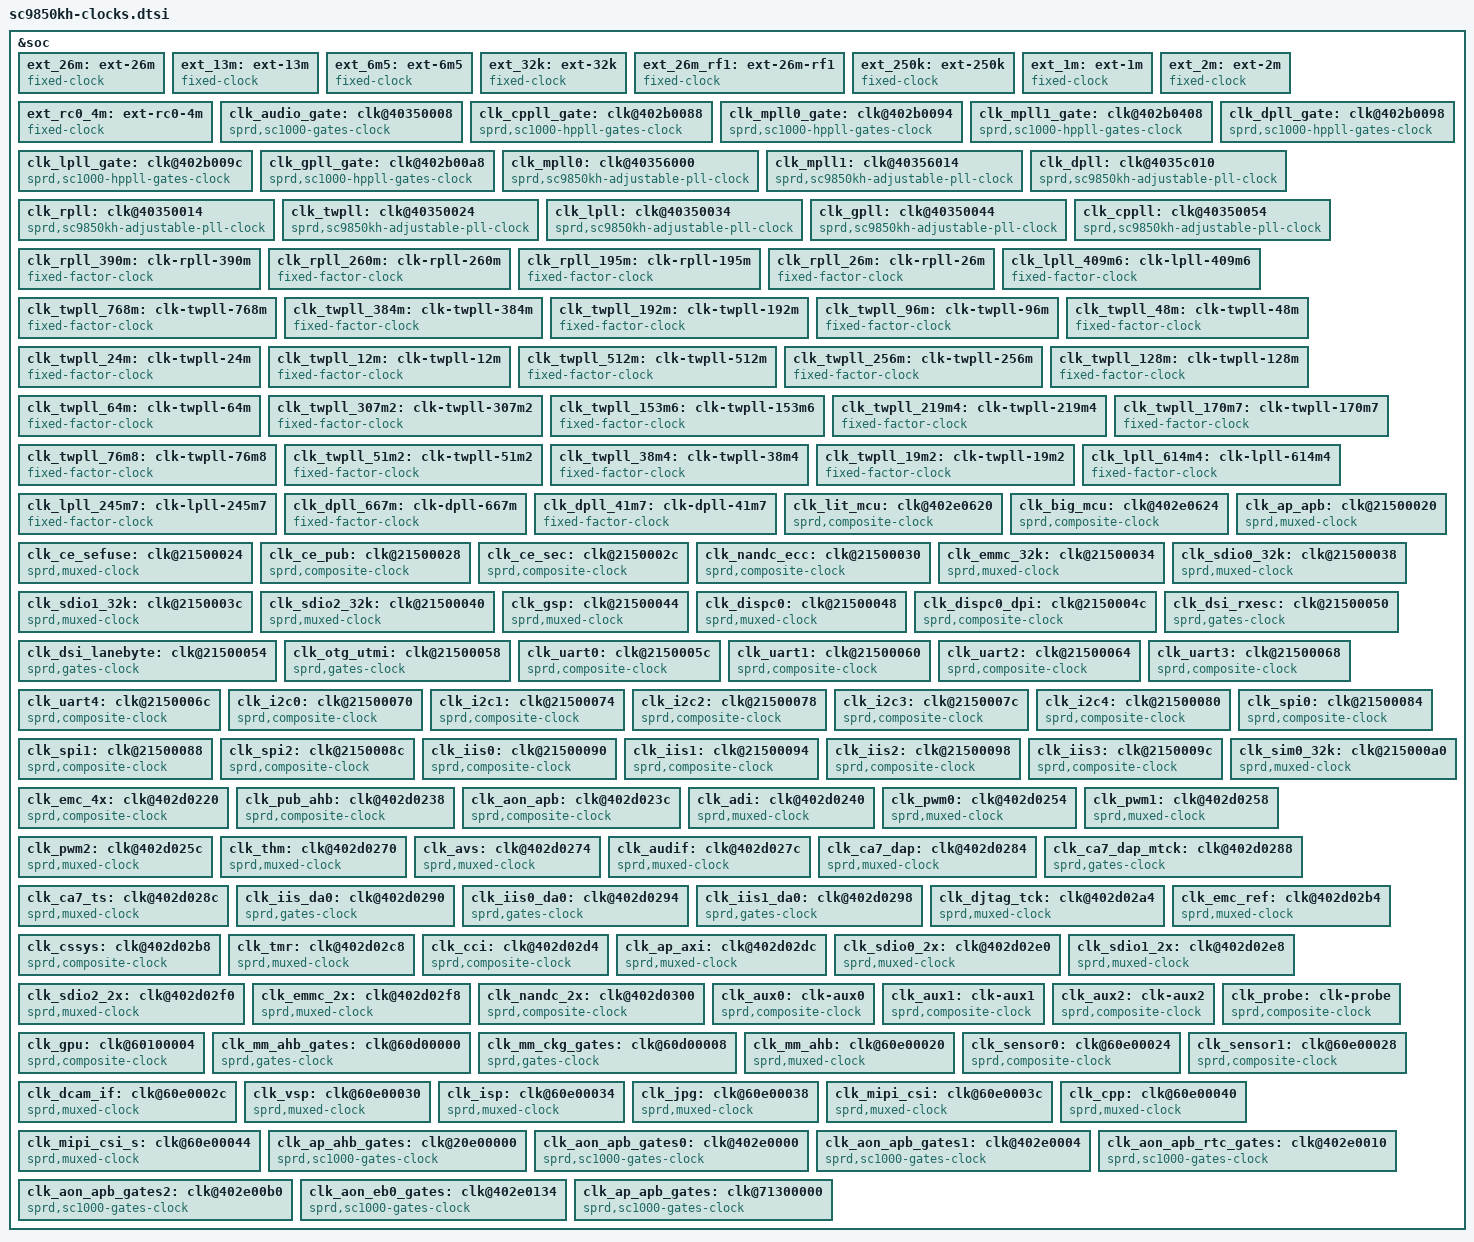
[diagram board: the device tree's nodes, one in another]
/*
 * Spreadtrum SC985x SoC DTS file
 *
 * Copyright (C) 2015, Spreadtrum Communications Inc.
 *
 * This file is licensed under a dual GPLv2 or X11 license.
 */

&soc {
	ext_26m: ext-26m {
		compatible = "fixed-clock";
		#clock-cells = <0>;
		clock-frequency = <26000000>;
		clock-output-names = "ext_26m";
	};

	ext_13m: ext-13m {
		compatible = "fixed-clock";
		#clock-cells = <0>;
		clock-frequency = <13000000>;
		clock-output-names = "ext_13m";
	};

	ext_6m5: ext-6m5 {
		compatible = "fixed-clock";
		#clock-cells = <0>;
		clock-frequency = <6500000>;
		clock-output-names = "ext_6m5";
	};

	ext_32k: ext-32k {
		compatible = "fixed-clock";
		#clock-cells = <0>;
		clock-frequency = <32768>;
		clock-output-names = "ext_32k";
	};

	ext_26m_rf1: ext-26m-rf1 {
		compatible = "fixed-clock";
		#clock-cells = <0>;
		clock-frequency = <26000000>;
		clock-output-names = "ext_26m_rf1";
	};

	ext_250k: ext-250k {
		compatible = "fixed-clock";
		#clock-cells = <0>;
		clock-frequency = <250000>;
		clock-output-names = "ext_250k";
	};

	ext_1m: ext-1m {
		compatible = "fixed-clock";
		#clock-cells = <0>;
		clock-frequency = <1000000>;
		clock-output-names = "ext_1m";
	};

	ext_2m: ext-2m {
		compatible = "fixed-clock";
		#clock-cells = <0>;
		clock-frequency = <2000000>;
		clock-output-names = "ext_2m";
	};

	ext_rc0_4m: ext-rc0-4m {
		compatible = "fixed-clock";
		#clock-cells = <0>;
		clock-frequency = <4000000>;
		clock-output-names = "ext_rc0_4m";
	};

	clk_audio_gate: clk@40350008 {
		compatible = "sprd,sc1000-gates-clock";
		#clock-cells = <1>;
		sprd,gates-msk = <0x80000>;
		reg = <0x0 0x40350008 0x0 0x3000>;
		clocks = <&ext_26m>;
		clock-output-names = "clk_audio_gate";
	};

	/* PLL gates */
	clk_cppll_gate: clk@402b0088 {
		compatible = "sprd,sc1000-hppll-gates-clock";
		#clock-cells = <1>;
		sprd,gates-msk = <0x1>;
		reg = <0 0x402b0088 0 0x3000>;
		clocks = <&ext_26m>;
		clock-output-names = "clk_cppll_gate";
	};

	clk_mpll0_gate: clk@402b0094 {
		compatible = "sprd,sc1000-hppll-gates-clock";
		#clock-cells = <1>;
		sprd,gates-msk = <0x1>;
		reg = <0 0x402b0094 0 0x3000>;
		clocks = <&ext_26m>;
		clock-output-names = "clk_mpll0_gate";
	};

	clk_mpll1_gate: clk@402b0408 {
		compatible = "sprd,sc1000-hppll-gates-clock";
		#clock-cells = <1>;
		sprd,gates-msk = <0x1>;
		reg = <0 0x402b0408 0 0x3000>;
		clocks = <&ext_26m>;
		clock-output-names = "clk_mpll1_gate";
	};

	clk_dpll_gate: clk@402b0098 {
		compatible = "sprd,sc1000-hppll-gates-clock";
		#clock-cells = <1>;
		sprd,gates-msk = <0x1>;
		reg = <0 0x402b0098 0 0x3000>;
		clocks = <&ext_26m>;
		clock-output-names = "clk_dpll_gate";
	};

	clk_lpll_gate: clk@402b009c {
		compatible = "sprd,sc1000-hppll-gates-clock";
		#clock-cells = <1>;
		sprd,gates-msk = <0x1>;
		reg = <0 0x402b009c 0 0x3000>;
		clocks = <&ext_26m>;
		clock-output-names = "clk_lpll_gate";
	};

	clk_gpll_gate: clk@402b00a8 {
		compatible = "sprd,sc1000-hppll-gates-clock";
		#clock-cells = <1>;
		sprd,gates-msk = <0x1>;
		reg = <0 0x402b00a8 0 0x3000>;
		clocks = <&ext_26m>;
		clock-output-names = "clk_gpll_gate";
	};

	/* PLL Clocks */
	clk_mpll0: clk@40356000 {
		compatible = "sprd,sc9850kh-adjustable-pll-clock";
		#clock-cells = <0>;
		reg = <0 0x40356000 0 0x4>,
		      <0 0x40356004 0 0x4>,
		      <0 0x40356008 0 0x4>;
		clocks = <&clk_mpll0_gate 0>;
		clock-output-names = "clk_mpll0";
	};

	clk_mpll1: clk@40356014 {
		compatible = "sprd,sc9850kh-adjustable-pll-clock";
		#clock-cells = <0>;
		reg = <0 0x40356014 0 0x4>,
		      <0 0x40356018 0 0x4>,
		      <0 0x4035601c 0 0x4>;
		clocks = <&clk_mpll1_gate 0>;
		clock-output-names = "clk_mpll1";
	};

	clk_dpll: clk@4035c010 {
		compatible = "sprd,sc9850kh-adjustable-pll-clock";
		#clock-cells = <0>;
		reg = <0 0x4035c010 0 0x4>,
		      <0 0x4035c014 0 0x4>;
		clocks = <&clk_dpll_gate 0>;
		clock-output-names = "clk_dpll";
	};

	clk_rpll: clk@40350014 {
		compatible = "sprd,sc9850kh-adjustable-pll-clock";
		#clock-cells = <0>;
		reg = <0 0x40350014 0 0x4>,
		      <0 0x40350018 0 0x4>,
		      <0 0x4035001c 0 0x4>;
		clocks = <&ext_26m>;
		clock-output-names = "clk_rpll";
	};

	clk_twpll: clk@40350024 {
		compatible = "sprd,sc9850kh-adjustable-pll-clock";
		#clock-cells = <0>;
		reg = <0 0x40350024 0 0x4>,
		      <0 0x40350028 0 0x4>,
		      <0 0x4035002c 0 0x4>;
		clocks = <&ext_26m>;
		clock-output-names = "clk_twpll";
	};

	clk_lpll: clk@40350034 {
		compatible = "sprd,sc9850kh-adjustable-pll-clock";
		#clock-cells = <0>;
		reg = <0 0x40350034 0 0x4>,
		      <0 0x40350038 0 0x4>,
		      <0 0x4035003c 0 0x4>;
		clocks = <&clk_lpll_gate 0>;
		clock-output-names = "clk_lpll";
	};

	clk_gpll: clk@40350044 {
		compatible = "sprd,sc9850kh-adjustable-pll-clock";
		#clock-cells = <0>;
		reg = <0 0x40350044 0 0x4>,
		      <0 0x40350048 0 0x4>,
		      <0 0x4035004c 0 0x4>;
		clocks = <&clk_gpll_gate 0>;
		clock-output-names = "clk_gpll";
	};


	clk_cppll: clk@40350054 {
		compatible = "sprd,sc9850kh-adjustable-pll-clock";
		#clock-cells = <0>;
		reg = <0 0x40350054 0 0x4>,
		      <0 0x40350058 0 0x4>,
		      <0 0x4035005c 0 0x4>;
		clocks = <&clk_cppll_gate 0>;
		clock-output-names = "clk_cppll";
	};

	/* RPLL divider clocks */
	clk_rpll_390m: clk-rpll-390m {
		compatible = "fixed-factor-clock";
		#clock-cells = <0>;
		clock-mult = <1>;
		clock-div  = <2>;
		clocks = <&clk_rpll>;
		clock-output-names = "clk_rpll_390m";
	};

	clk_rpll_260m: clk-rpll-260m {
		compatible = "fixed-factor-clock";
		#clock-cells = <0>;
		clock-mult = <1>;
		clock-div  = <3>;
		clocks = <&clk_rpll>;
		clock-output-names = "clk_rpll_260m";
	};

	clk_rpll_195m: clk-rpll-195m {
		compatible = "fixed-factor-clock";
		#clock-cells = <0>;
		clock-mult = <1>;
		clock-div  = <4>;
		clocks = <&clk_rpll>;
		clock-output-names = "clk_rpll_195m";
	};

	clk_rpll_26m: clk-rpll-26m {
		compatible = "fixed-factor-clock";
		#clock-cells = <0>;
		clock-mult = <1>;
		clock-div  = <30>;
		clocks = <&clk_rpll>;
		clock-output-names = "clk_rpll_26m";
	};

	/* LPLL divider clocks */
	clk_lpll_409m6: clk-lpll-409m6 {
		compatible = "fixed-factor-clock";
		#clock-cells = <0>;
		clock-mult = <1>;
		clock-div  = <3>;
		clocks = <&clk_lpll>;
		clock-output-names = "clk_lpll_409m6";
	};

	/* TWPLL divider clocks */
	clk_twpll_768m: clk-twpll-768m {
		compatible = "fixed-factor-clock";
		#clock-cells = <0>;
		clock-mult = <1>;
		clock-div  = <2>;
		clocks = <&clk_twpll>;
		clock-output-names = "clk_twpll_768m";
	};

	clk_twpll_384m: clk-twpll-384m {
		compatible = "fixed-factor-clock";
		#clock-cells = <0>;
		clock-mult = <1>;
		clock-div  = <4>;
		clocks = <&clk_twpll>;
		clock-output-names = "clk_twpll_384m";
	};

	clk_twpll_192m: clk-twpll-192m {
		compatible = "fixed-factor-clock";
		#clock-cells = <0>;
		clock-mult = <1>;
		clock-div  = <8>;
		clocks = <&clk_twpll>;
		clock-output-names = "clk_twpll_192m";
	};

	clk_twpll_96m: clk-twpll-96m {
		compatible = "fixed-factor-clock";
		#clock-cells = <0>;
		clock-mult = <1>;
		clock-div  = <16>;
		clocks = <&clk_twpll>;
		clock-output-names = "clk_twpll_96m";
	};

	clk_twpll_48m: clk-twpll-48m {
		compatible = "fixed-factor-clock";
		#clock-cells = <0>;
		clock-mult = <1>;
		clock-div  = <32>;
		clocks = <&clk_twpll>;
		clock-output-names = "clk_twpll_48m";
	};

	clk_twpll_24m: clk-twpll-24m {
		compatible = "fixed-factor-clock";
		#clock-cells = <0>;
		clock-mult = <1>;
		clock-div  = <64>;
		clocks = <&clk_twpll>;
		clock-output-names = "clk_twpll_24m";
	};

	clk_twpll_12m: clk-twpll-12m {
		compatible = "fixed-factor-clock";
		#clock-cells = <0>;
		clock-mult = <1>;
		clock-div  = <128>;
		clocks = <&clk_twpll>;
		clock-output-names = "clk_twpll_12m";
	};

	clk_twpll_512m: clk-twpll-512m {
		compatible = "fixed-factor-clock";
		#clock-cells = <0>;
		clock-mult = <1>;
		clock-div  = <3>;
		clocks = <&clk_twpll>;
		clock-output-names = "clk_twpll_512m";
	};

	clk_twpll_256m: clk-twpll-256m {
		compatible = "fixed-factor-clock";
		#clock-cells = <0>;
		clock-mult = <1>;
		clock-div  = <6>;
		clocks = <&clk_twpll>;
		clock-output-names = "clk_twpll_256m";
	};

	clk_twpll_128m: clk-twpll-128m {
		compatible = "fixed-factor-clock";
		#clock-cells = <0>;
		clock-mult = <1>;
		clock-div  = <12>;
		clocks = <&clk_twpll>;
		clock-output-names = "clk_twpll_128m";
	};

	clk_twpll_64m: clk-twpll-64m {
		compatible = "fixed-factor-clock";
		#clock-cells = <0>;
		clock-mult = <1>;
		clock-div  = <24>;
		clocks = <&clk_twpll>;
		clock-output-names = "clk_twpll_64m";
	};

	clk_twpll_307m2: clk-twpll-307m2 {
		compatible = "fixed-factor-clock";
		#clock-cells = <0>;
		clock-mult = <1>;
		clock-div  = <5>;
		clocks = <&clk_twpll>;
		clock-output-names = "clk_twpll_307m2";
	};

	clk_twpll_153m6: clk-twpll-153m6 {
		compatible = "fixed-factor-clock";
		#clock-cells = <0>;
		clock-mult = <1>;
		clock-div  = <10>;
		clocks = <&clk_twpll>;
		clock-output-names = "clk_twpll_153m6";
	};

	clk_twpll_219m4: clk-twpll-219m4 {
		compatible = "fixed-factor-clock";
		#clock-cells = <0>;
		clock-mult = <1>;
		clock-div  = <7>;
		clocks = <&clk_twpll>;
		clock-output-names = "clk_twpll_219m4";
	};

	clk_twpll_170m7: clk-twpll-170m7 {
		compatible = "fixed-factor-clock";
		#clock-cells = <0>;
		clock-mult = <1>;
		clock-div  = <9>;
		clocks = <&clk_twpll>;
		clock-output-names = "clk_twpll_170m7";
	};

	clk_twpll_76m8: clk-twpll-76m8 {
		compatible = "fixed-factor-clock";
		#clock-cells = <0>;
		clock-mult = <1>;
		clock-div  = <20>;
		clocks = <&clk_twpll>;
		clock-output-names = "clk_twpll_76m8";
	};

	clk_twpll_51m2: clk-twpll-51m2 {
		compatible = "fixed-factor-clock";
		#clock-cells = <0>;
		clock-mult = <1>;
		clock-div  = <30>;
		clocks = <&clk_twpll>;
		clock-output-names = "clk_twpll_51m2";
	};

	clk_twpll_38m4: clk-twpll-38m4 {
		compatible = "fixed-factor-clock";
		#clock-cells = <0>;
		clock-mult = <1>;
		clock-div  = <40>;
		clocks = <&clk_twpll>;
		clock-output-names = "clk_twpll_38m4";
	};

	clk_twpll_19m2: clk-twpll-19m2 {
		compatible = "fixed-factor-clock";
		#clock-cells = <0>;
		clock-mult = <1>;
		clock-div  = <80>;
		clocks = <&clk_twpll>;
		clock-output-names = "clk_twpll_19m2";
	};

	/* LTEPLL0 divider clock */
	clk_lpll_614m4: clk-lpll-614m4 {
		compatible = "fixed-factor-clock";
		#clock-cells = <0>;
		clock-mult = <1>;
		clock-div = <2>;
		clocks = <&clk_lpll>;
		clock-output-names = "clk_lpll_614m4";
	};

	clk_lpll_245m7: clk-lpll-245m7 {
		compatible = "fixed-factor-clock";
		#clock-cells = <0>;
		clock-mult = <1>;
		clock-div = <5>;
		clocks = <&clk_lpll>;
		clock-output-names = "clk_lpll_245m7";
	};
	/* DPLL divider clock */
	clk_dpll_667m: clk-dpll-667m {
		compatible = "fixed-factor-clock";
		#clock-cells = <0>;
		clock-mult = <1>;
		clock-div = <2>;
		clocks = <&clk_dpll>;
		clock-output-names = "clk_dpll_667m";
	};

	clk_dpll_41m7: clk-dpll-41m7 {
		compatible = "fixed-factor-clock";
		#clock-cells = <0>;
		clock-mult = <1>;
		clock-div = <32>;
		clocks = <&clk_dpll>;
		clock-output-names = "clk_dpll_41m7";
	};

	clk_lit_mcu: clk@402e0620 {
		compatible = "sprd,composite-clock";
		#clock-cells = <0>;
		reg = <0 0x402e0620 0 0x4>;	/* select reg and divider reg */
		sprd,mux-msk = <0xf>;
		sprd,div-msk = <0x70>;
		clocks = <&ext_26m>, <&clk_twpll_76m8>, <&clk_twpll_256m>,
			<&clk_twpll_384m>, <&clk_twpll_512m>, <&clk_twpll_768m>,
			<&clk_lpll>, <&clk_lpll>, <&clk_mpll0>;
		clock-output-names = "clk_lit_mcu";
	};

	clk_big_mcu: clk@402e0624 {
		compatible = "sprd,composite-clock";
		#clock-cells = <0>;
		reg = <0 0x402e0624 0 0x4>;	/* select reg and divider reg */
		sprd,mux-msk = <0xf>;
		sprd,div-msk = <0x70>;
		clocks = <&ext_26m>, <&clk_twpll_76m8>, <&clk_twpll_256m>,
			<&clk_twpll_384m>, <&clk_twpll_512m>, <&clk_twpll_768m>,
			<&clk_lpll>, <&clk_lpll>, <&clk_mpll1>;
		clock-output-names = "clk_big_mcu";
	};

	/* Ap clocks */
	clk_ap_apb: clk@21500020 {
		compatible = "sprd,muxed-clock";
		#clock-cells = <0>;
		reg = <0 0x21500020 0 0x4>;
		sprd,mux-msk = <0x3>;
		clocks = <&ext_26m>, <&clk_twpll_64m>, <&clk_twpll_96m>,
			 <&clk_twpll_128m>;
		clock-output-names = "clk_ap_apb";
	};

	clk_ce_sefuse: clk@21500024 {
		compatible = "sprd,muxed-clock";
		#clock-cells = <0>;
		reg = <0 0x21500024 0 0x4>;
		sprd,mux-msk = <0x1>;
		clocks = <&ext_26m>;
		clock-output-names = "clk_ce_sefuse";
	};

	clk_ce_pub: clk@21500028 {
		compatible = "sprd,composite-clock";
		#clock-cells = <0>;
		reg = <0 0x21500028 0 0x4>;
		sprd,mux-msk = <0x1>;
		sprd,div-msk = <0x700>;
		clocks = <&ext_26m>, <&clk_twpll_256m>;
		clock-output-names = "clk_ce_pub";
	};

	clk_ce_sec: clk@2150002c {
		compatible = "sprd,composite-clock";
		#clock-cells = <0>;
		reg = <0 0x2150002c 0 0x4>;
		sprd,mux-msk = <0x1>;
		sprd,div-msk = <0x700>;
		clocks = <&ext_26m>, <&clk_twpll_256m>;
		clock-output-names = "clk_ce_sec";
	};

	clk_nandc_ecc: clk@21500030 {
		compatible = "sprd,composite-clock";
		#clock-cells = <0>;
		reg = <0 0x21500030 0 0x4>;
		sprd,mux-msk = <0x1>;
		sprd,div-msk = <0x700>;
		clocks = <&ext_26m>, <&clk_twpll_256m>, <&clk_twpll_307m2>;
		clock-output-names = "clk_nandc_ecc";
	};

	clk_emmc_32k: clk@21500034 {
		compatible = "sprd,muxed-clock";
		#clock-cells = <0>;
		reg = <0 0x21500034 0 0x4>;
		sprd,mux-msk = <0x1>;
		clocks = <&ext_32k>, <&ext_26m>;
		clock-output-names = "clk_emmc_32k";
	};

	clk_sdio0_32k: clk@21500038 {
		compatible = "sprd,muxed-clock";
		#clock-cells = <0>;
		reg = <0 0x21500038 0 0x4>;
		sprd,mux-msk = <0x1>;
		clocks = <&ext_32k>, <&ext_26m>;
		clock-output-names = "clk_sdio0_32k";
	};

	clk_sdio1_32k: clk@2150003c {
		compatible = "sprd,muxed-clock";
		#clock-cells = <0>;
		reg = <0 0x2150003c 0 0x4>;
		sprd,mux-msk = <0x1>;
		clocks = <&ext_32k>, <&ext_26m>;
		clock-output-names = "clk_sdio1_32k";
	};

	clk_sdio2_32k: clk@21500040 {
		compatible = "sprd,muxed-clock";
		#clock-cells = <0>;
		reg = <0 0x21500040 0 0x4>;
		sprd,mux-msk = <0x1>;
		clocks = <&ext_32k>, <&ext_26m>;
		clock-output-names = "clk_sdio2_32k";
	};

	clk_gsp: clk@21500044 {
		compatible = "sprd,muxed-clock";
		#clock-cells = <0>;
		reg = <0 0x21500044 0 0x4>;
		sprd,mux-msk = <0x3>;
		clocks = <&clk_twpll_153m6>, <&clk_twpll_192m>,
			 <&clk_twpll_256m>, <&clk_twpll_307m2>;
		clock-output-names = "clk_gsp";
	};

	clk_dispc0: clk@21500048 {
		compatible = "sprd,muxed-clock";
		#clock-cells = <0>;
		reg = <0 0x21500048 0 0x4>;
		sprd,mux-msk = <0x3>;
		clocks = <&clk_twpll_153m6>, <&clk_twpll_192m>,
			 <&clk_twpll_256m>, <&clk_twpll_384m>;
		clock-output-names = "clk_dispc0";
	};

	clk_dispc0_dpi: clk@2150004c {
		compatible = "sprd,composite-clock";
		#clock-cells = <0>;
		reg = <0 0x2150004c 0 0x4>; /* select and divider reg */
		sprd,mux-msk = <0x3>;
		sprd,div-msk = <0xf00>;
		clocks = <&clk_twpll_128m>, <&clk_twpll_153m6>,
			 <&clk_twpll_192m>, <&clk_twpll_256m>;
		clock-output-names = "clk_dispc0_dpi";
	};

	clk_dsi_rxesc: clk@21500050 {
		compatible = "sprd,gates-clock";
		#clock-cells = <1>;
		reg = <0 0x21500050 0 0x4>;
		sprd,gates-msk = <0x10000>;
		clocks = <&clk_ap_apb>;
		clock-output-names = "clk_dsi_rxesc";
	};

	clk_dsi_lanebyte: clk@21500054 {
		compatible = "sprd,gates-clock";
		#clock-cells = <1>;
		reg = <0 0x21500054 0 0x4>;
		sprd,gates-msk = <0x10000>;
		clocks = <&clk_ap_apb>;
		clock-output-names = "clk_dsi_lanebyte";
	};

	clk_otg_utmi: clk@21500058 {
		compatible = "sprd,gates-clock";
		#clock-cells = <1>;
		reg = <0 0x21500058 0 0x4>;
		sprd,gates-msk = <0x10000>;
		clocks = <&clk_ap_apb>;
		clock-output-names = "clk_otg_utmi";
	};

	clk_uart0: clk@2150005c {
		compatible = "sprd,composite-clock";
		#clock-cells = <0>;
		reg = <0 0x2150005c 0 0x4>; /* select and divider reg */
		sprd,mux-msk = <0x3>;
		sprd,div-msk = <0x700>;
		clocks = <&ext_26m>, <&clk_twpll_48m>, <&clk_twpll_51m2>,
			 <&clk_twpll_96m>;
		clock-output-names = "clk_uart0";
	};

	clk_uart1: clk@21500060 {
		compatible = "sprd,composite-clock";
		#clock-cells = <0>;
		reg = <0 0x21500060 0 0x4>; /* select and divider reg */
		sprd,mux-msk = <0x3>;
		sprd,div-msk = <0x700>;
		clocks = <&ext_26m>, <&clk_twpll_48m>, <&clk_twpll_51m2>,
			 <&clk_twpll_96m>;
		clock-output-names = "clk_uart1";
	};

	clk_uart2: clk@21500064 {
		compatible = "sprd,composite-clock";
		#clock-cells = <0>;
		reg = <0 0x21500064 0 0x4>; /* select and divider reg */
		sprd,mux-msk = <0x3>;
		sprd,div-msk = <0x700>;
		clocks = <&ext_26m>, <&clk_twpll_48m>, <&clk_twpll_51m2>,
			 <&clk_twpll_96m>;
		clock-output-names = "clk_uart2";
	};

	clk_uart3: clk@21500068 {
		compatible = "sprd,composite-clock";
		#clock-cells = <0>;
		reg = <0 0x21500068 0 0x4>; /* select and divider reg */
		sprd,mux-msk = <0x3>;
		sprd,div-msk = <0x700>;
		clocks = <&ext_26m>, <&clk_twpll_48m>, <&clk_twpll_51m2>,
			 <&clk_twpll_96m>;
		clock-output-names = "clk_uart3";
	};

	clk_uart4: clk@2150006c {
		compatible = "sprd,composite-clock";
		#clock-cells = <0>;
		reg = <0 0x2150006c 0 0x4>; /* select and divider reg */
		sprd,mux-msk = <0x3>;
		sprd,div-msk = <0x700>;
		clocks = <&ext_26m>, <&clk_twpll_48m>, <&clk_twpll_51m2>,
			 <&clk_twpll_96m>;
		clock-output-names = "clk_uart4";
	};

	clk_i2c0: clk@21500070 {
		compatible = "sprd,composite-clock";
		#clock-cells = <0>;
		reg = <0 0x21500070 0 0x4>; /* select and divider reg */
		sprd,mux-msk = <0x3>;
		sprd,div-msk = <0x700>;
		clocks = <&ext_26m>, <&clk_twpll_48m>, <&clk_twpll_51m2>,
			 <&clk_twpll_153m6>;
		clock-output-names = "clk_i2c0";
	};

	clk_i2c1: clk@21500074 {
		compatible = "sprd,composite-clock";
		#clock-cells = <0>;
		reg = <0 0x21500074 0 0x4>; /* select and divider reg */
		sprd,mux-msk = <0x3>;
		sprd,div-msk = <0x700>;
		clocks = <&ext_26m>, <&clk_twpll_48m>, <&clk_twpll_51m2>,
			 <&clk_twpll_153m6>;
		clock-output-names = "clk_i2c1";
	};

	clk_i2c2: clk@21500078 {
		compatible = "sprd,composite-clock";
		#clock-cells = <0>;
		reg = <0 0x21500078 0 0x4>; /* select and divider reg */
		sprd,mux-msk = <0x3>;
		sprd,div-msk = <0x700>;
		clocks = <&ext_26m>, <&clk_twpll_48m>, <&clk_twpll_51m2>,
			 <&clk_twpll_153m6>;
		clock-output-names = "clk_i2c2";
	};

	clk_i2c3: clk@2150007c {
		compatible = "sprd,composite-clock";
		#clock-cells = <0>;
		reg = <0 0x2150007c 0 0x4>; /* select and divider reg */
		sprd,mux-msk = <0x3>;
		sprd,div-msk = <0x700>;
		clocks = <&ext_26m>, <&clk_twpll_48m>, <&clk_twpll_51m2>,
			 <&clk_twpll_153m6>;
		clock-output-names = "clk_i2c3";
	};

	clk_i2c4: clk@21500080 {
		compatible = "sprd,composite-clock";
		#clock-cells = <0>;
		reg = <0 0x21500080 0 0x4>; /* select and divider reg */
		sprd,mux-msk = <0x3>;
		sprd,div-msk = <0x700>;
		clocks = <&ext_26m>, <&clk_twpll_48m>, <&clk_twpll_51m2>,
			 <&clk_twpll_153m6>;
		clock-output-names = "clk_i2c4";
	};

	clk_spi0: clk@21500084 {
		compatible = "sprd,composite-clock";
		#clock-cells = <0>;
		reg = <0 0x21500084 0 0x4>; /* select and divider reg */
		sprd,mux-msk = <0x3>;
		sprd,div-msk = <0x700>;
		clocks = <&ext_26m>, <&clk_twpll_128m>, <&clk_twpll_153m6>,
			 <&clk_twpll_192m>;
		clock-output-names = "clk_spi0";
	};

	clk_spi1: clk@21500088 {
		compatible = "sprd,composite-clock";
		#clock-cells = <0>;
		reg = <0 0x21500088 0 0x4>; /* select and divider reg */
		sprd,mux-msk = <0x3>;
		sprd,div-msk = <0x700>;
		clocks = <&ext_26m>, <&clk_twpll_128m>, <&clk_twpll_153m6>,
			 <&clk_twpll_192m>;
		clock-output-names = "clk_spi1";
	};

	clk_spi2: clk@2150008c {
		compatible = "sprd,composite-clock";
		#clock-cells = <0>;
		reg = <0 0x2150008c 0 0x4>; /* select and divider reg */
		sprd,mux-msk = <0x3>;
		sprd,div-msk = <0x700>;
		clocks = <&ext_26m>, <&clk_twpll_128m>, <&clk_twpll_153m6>,
			 <&clk_twpll_192m>;
		clock-output-names = "clk_spi2";
	};

	clk_iis0: clk@21500090 {
		compatible = "sprd,composite-clock";
		#clock-cells = <0>;
		reg = <0 0x21500090 0 0x4>; /* select and divider reg */
		sprd,mux-msk = <0x3>;
		sprd,div-msk = <0x700>;
		clocks = <&ext_26m>, <&clk_twpll_128m>, <&clk_twpll_153m6>;
		clock-output-names = "clk_iis0";
	};

	clk_iis1: clk@21500094 {
		compatible = "sprd,composite-clock";
		#clock-cells = <0>;
		reg = <0 0x21500094 0 0x4>; /* select and divider reg */
		sprd,mux-msk = <0x3>;
		sprd,div-msk = <0x700>;
		clocks = <&ext_26m>, <&clk_twpll_128m>, <&clk_twpll_153m6>;
		clock-output-names = "clk_iis1";
	};

	clk_iis2: clk@21500098 {
		compatible = "sprd,composite-clock";
		#clock-cells = <0>;
		reg = <0 0x21500098 0 0x4>; /* select and divider reg */
		sprd,mux-msk = <0x3>;
		sprd,div-msk = <0x700>;
		clocks = <&ext_26m>, <&clk_twpll_128m>, <&clk_twpll_153m6>;
		clock-output-names = "clk_iis2";
	};

	clk_iis3: clk@2150009c {
		compatible = "sprd,composite-clock";
		#clock-cells = <0>;
		reg = <0 0x2150009c 0 0x4>; /* select and divider reg */
		sprd,mux-msk = <0x3>;
		sprd,div-msk = <0x700>;
		clocks = <&ext_26m>, <&clk_twpll_128m>, <&clk_twpll_153m6>;
		clock-output-names = "clk_iis3";
	};

	clk_sim0_32k: clk@215000a0 {
		compatible = "sprd,muxed-clock";
		#clock-cells = <0>;
		reg = <0 0x215000a0 0 0x4>;
		sprd,mux-msk = <0x1>;
		clocks = <&ext_32k>, <&ext_26m>;
		clock-output-names = "clk_sim0_32k";
	};
	/* Aon Clock */
	clk_emc_4x: clk@402d0220 {
		compatible = "sprd,composite-clock";
		#clock-cells = <0>;
		reg = <0 0x402d0220 0 0x4>; /* select and divider reg */
		sprd,mux-msk = <0x3>;
		sprd,div-msk = <0x300>;
		clocks = <&ext_26m>, <&clk_lpll_614m4>, <&clk_twpll_768m>,
			 <&clk_dpll>;
		clock-output-names = "clk_emc_4x";
	};

	clk_pub_ahb: clk@402d0238 {
		compatible = "sprd,composite-clock";
		#clock-cells = <0>;
		reg = <0 0x402d0238 0 0x4>; /* select and divider reg */
		sprd,mux-msk = <0x3>;
		sprd,div-msk = <0x300>;
		clocks = <&ext_26m>, <&ext_rc0_4m>, <&clk_twpll_96m>,
			 <&clk_twpll_128m>;
		clock-output-names = "clk_pub_ahb";
	};

	clk_aon_apb: clk@402d023c {
		compatible = "sprd,composite-clock";
		#clock-cells = <0>;
		reg = <0 0x402d023c 0 0x4>; /* select and divider reg */
		sprd,mux-msk = <0x3>;
		sprd,div-msk = <0x300>;
		clocks = <&ext_rc0_4m>, <&ext_26m>, <&clk_twpll_96m>,
			 <&clk_twpll_128m>;
		clock-output-names = "clk_aon_apb";
	};

	clk_adi: clk@402d0240 {
		compatible = "sprd,muxed-clock";
		#clock-cells = <0>;
		reg = <0 0x402d0240 0 0x4>;
		sprd,mux-msk = <0x3>;
		clocks = <&ext_26m>, <&ext_rc0_4m>, <&clk_twpll_38m4>,
			 <&clk_twpll_51m2>;
		clock-output-names = "clk_adi";
	};

	clk_pwm0: clk@402d0254 {
		compatible = "sprd,muxed-clock";
		#clock-cells = <0>;
		reg = <0 0x402d0254 0 0x4>;
		sprd,mux-msk = <0x3>;
		clocks = <&ext_32k>, <&clk_rpll_26m>, <&ext_26m>,
			 <&clk_twpll_48m>;
		clock-output-names = "clk_pwm0";
	};

	clk_pwm1: clk@402d0258 {
		compatible = "sprd,muxed-clock";
		#clock-cells = <0>;
		reg = <0 0x402d0258 0 0x4>;
		sprd,mux-msk = <0x3>;
		clocks = <&ext_32k>, <&clk_rpll_26m>, <&ext_26m>,
			 <&clk_twpll_48m>;
		clock-output-names = "clk_pwm1";
	};

	clk_pwm2: clk@402d025c {
		compatible = "sprd,muxed-clock";
		#clock-cells = <0>;
		reg = <0 0x402d025c 0 0x4>;
		sprd,mux-msk = <0x3>;
		clocks = <&ext_32k>, <&clk_rpll_26m>, <&ext_26m>,
			 <&clk_twpll_48m>;
		clock-output-names = "clk_pwm2";
	};

	clk_thm: clk@402d0270 {
		compatible = "sprd,muxed-clock";
		#clock-cells = <0>;
		reg = <0 0x402d0270 0 0x4>;
		sprd,mux-msk = <0x1>;
		clocks = <&ext_32k>, <&ext_250k>;
		clock-output-names = "clk_thm";
	};

	clk_avs: clk@402d0274 {
		compatible = "sprd,muxed-clock";
		#clock-cells = <0>;
		reg = <0 0x402d0274 0 0x4>;
		sprd,mux-msk = <0x3>;
		clocks = <&ext_26m>, <&clk_twpll_48m>, <&clk_twpll_51m2>,
			 <&clk_twpll_96m>;
		clock-output-names = "clk_avs";
	};

	clk_audif: clk@402d027c {
		compatible = "sprd,muxed-clock";
		#clock-cells = <0>;
		reg = <0 0x402d027c 0 0x4>;
		sprd,mux-msk = <0x3>;
		clocks = <&ext_26m>, <&clk_twpll_38m4>, <&clk_twpll_51m2>;
		clock-output-names = "clk_audif";
	};

	clk_ca7_dap: clk@402d0284 {
		compatible = "sprd,muxed-clock";
		#clock-cells = <0>;
		reg = <0 0x402d0284 0 0x4>;
		sprd,mux-msk = <0x3>;
		clocks = <&ext_26m>, <&clk_twpll_76m8>, <&clk_twpll_128m>,
			 <&clk_twpll_153m6>;
		clock-output-names = "clk_ca7_dap";
	};

	clk_ca7_dap_mtck: clk@402d0288 {
		compatible = "sprd,gates-clock";
		#clock-cells = <1>;
		reg = <0 0x402d0288 0 0x4>;
		sprd,gates-msk = <0x10000>;
		clocks = <&clk_ap_apb>;
		clock-output-names = "clk_ca7_dap_mtck";
	};

	clk_ca7_ts: clk@402d028c {
		compatible = "sprd,muxed-clock";
		#clock-cells = <0>;
		reg = <0 0x402d028c 0 0x4>;
		sprd,mux-msk = <0x3>;
		clocks = <&ext_32k>, <&ext_26m>, <&clk_twpll_128m>,
			 <&clk_twpll_153m6>;
		clock-output-names = "clk_ca7_dap";
	};

	clk_iis_da0: clk@402d0290 {
		compatible = "sprd,gates-clock";
		#clock-cells = <1>;
		reg = <0 0x402d0290 0 0x4>;
		sprd,gates-msk = <0x10000>;
		clocks = <&clk_ap_apb>;
		clock-output-names = "clk_iis_da0";
	};

	clk_iis0_da0: clk@402d0294 {
		compatible = "sprd,gates-clock";
		#clock-cells = <1>;
		reg = <0 0x402d0294 0 0x4>;
		sprd,gates-msk = <0x10000>;
		clocks = <&clk_ap_apb>;
		clock-output-names = "clk_iis0_da0";
	};

	clk_iis1_da0: clk@402d0298 {
		compatible = "sprd,gates-clock";
		#clock-cells = <1>;
		reg = <0 0x402d0298 0 0x4>;
		sprd,gates-msk = <0x10000>;
		clocks = <&clk_ap_apb>;
		clock-output-names = "clk_iis1_da0";
	};

	clk_djtag_tck: clk@402d02a4 {
		compatible = "sprd,muxed-clock";
		#clock-cells = <0>;
		reg = <0 0x402d02a4 0 0x4>;
		sprd,mux-msk = <0x1>;
		clocks = <&ext_rc0_4m>, <&ext_26m>;
		clock-output-names = "clk_djtag_tck";
	};

	clk_emc_ref: clk@402d02b4 {
		compatible = "sprd,muxed-clock";
		#clock-cells = <0>;
		reg = <0 0x402d02b4 0 0x4>;
		sprd,mux-msk = <0x3>;
		clocks = <&ext_6m5>, <&ext_13m>, <&ext_26m>;
		clock-output-names = "clk_emc_ref";
	};

	clk_cssys: clk@402d02b8 {
		compatible = "sprd,composite-clock";
		#clock-cells = <0>;
		reg = <0 0x402d02b8 0 0x4>; /* select and divider reg */
		sprd,mux-msk = <0x7>;
		sprd,div-msk = <0x300>;
		clocks = <&ext_26m>, <&clk_twpll_96m>, <&clk_twpll_128m>,
			 <&clk_twpll_153m6>, <&clk_twpll_384m>,
			 <&clk_twpll_512m>, <&clk_dpll_667m>;
		clock-output-names = "clk_cssys";
	};

	clk_tmr: clk@402d02c8 {
		compatible = "sprd,muxed-clock";
		#clock-cells = <0>;
		reg = <0 0x402d02c8 0 0x4>;
		sprd,mux-msk = <0x3>;
		clocks = <&ext_rc0_4m>, <&ext_26m>;
		clock-output-names = "clk_tmr";
	};

	clk_cci: clk@402d02d4 {
		compatible = "sprd,composite-clock";
		#clock-cells = <0>;
		reg = <0 0x402d02d4 0 0x4>; /* select and divider reg */
		sprd,mux-msk = <0x7>;
		sprd,div-msk = <0x300>;
		clocks = <&ext_26m>, <&clk_twpll_153m6>, <&clk_twpll_384m>,
			 <&clk_twpll_512m>, <&clk_lpll_614m4>, <&clk_dpll_667m>;
		clock-output-names = "clk_cci";
	};

	clk_ap_axi: clk@402d02dc {
		compatible = "sprd,muxed-clock";
		#clock-cells = <0>;
		reg = <0 0x402d02dc 0 0x4>;
		sprd,mux-msk = <0x3>;
		clocks = <&ext_26m>, <&clk_twpll_76m8>,
			<&clk_twpll_128m>, <&clk_twpll_256m>;
		clock-output-names = "clk_ap_axi";
	};

	clk_sdio0_2x: clk@402d02e0 {
		compatible = "sprd,muxed-clock";
		#clock-cells = <0>;
		reg = <0 0x402d02e0 0 0x4>;
		sprd,mux-msk = <0x7>;
		clocks = <&ext_1m>, <&ext_26m>, <&clk_twpll_307m2>,
			 <&clk_twpll_384m>, <&clk_rpll_390m>,
			 <&clk_lpll_409m6>;
		clock-output-names = "clk_sdio0_2x";
	};

	clk_sdio1_2x: clk@402d02e8 {
		compatible = "sprd,muxed-clock";
		#clock-cells = <0>;
		reg = <0 0x402d02e8 0 0x4>;
		sprd,mux-msk = <0x7>;
		clocks = <&ext_1m>, <&ext_26m>, <&clk_twpll_307m2>,
			 <&clk_twpll_384m>, <&clk_rpll_390m>,
			 <&clk_lpll_409m6>;
		clock-output-names = "clk_sdio1_2x";
	};

	clk_sdio2_2x: clk@402d02f0 {
		compatible = "sprd,muxed-clock";
		#clock-cells = <0>;
		reg = <0 0x402d02f0 0 0x4>;
		sprd,mux-msk = <0x7>;
		clocks = <&ext_1m>, <&ext_26m>, <&clk_twpll_307m2>,
			 <&clk_twpll_384m>, <&clk_rpll_390m>,
			 <&clk_lpll_409m6>;
		clock-output-names = "clk_sdio2_2x";
	};

	clk_emmc_2x: clk@402d02f8 {
		compatible = "sprd,muxed-clock";
		#clock-cells = <0>;
		reg = <0 0x402d02f8 0 0x4>;
		sprd,mux-msk = <0x7>;
		clocks = <&ext_1m>, <&ext_26m>, <&clk_twpll_307m2>,
			 <&clk_twpll_384m>, <&clk_rpll_390m>,
			 <&clk_lpll_409m6>;
		clock-output-names = "clk_emmc_2x";
	};

	clk_nandc_2x: clk@402d0300 {
		compatible = "sprd,composite-clock";
		#clock-cells = <0>;
		reg = <0 0x402d0300 0 0x4>;
		sprd,mux-msk = <0xf>;
		sprd,div-msk = <0xf00>;
		clocks = <&ext_26m>, <&clk_twpll_153m6>, <&clk_twpll_170m7>,
			 <&clk_rpll_195m>, <&clk_twpll_219m4>, <&clk_lpll_245m7>,
			 <&clk_rpll_260m>, <&clk_twpll_307m2>, <&clk_rpll_390m>;
		clock-output-names = "clk_nandc_2x";
	};

	clk_aux0: clk-aux0 {
		compatible = "sprd,composite-clock";
		#clock-cells = <0>;
		reg = <0 0x402e0088 0 0x4>,
			<0 0x402e008c 0 0x4>;
		sprd,mux-msk = <0x1f>;
		sprd,div-msk = <0xf>;
		clocks = <&ext_32k>, <&ext_26m>, <&ext_26m>,
			 <&ext_rc0_4m>, <&clk_dpll_41m7>, <&clk_twpll_48m>;
		clock-output-names = "clk_aux0";
	};

	clk_aux1: clk-aux1 {
		compatible = "sprd,composite-clock";
		#clock-cells = <0>;
		reg = <0 0x402e0088 0 0x4>,
			<0 0x402e008c 0 0x4>;
		sprd,mux-msk = <0x1f00>;
		sprd,div-msk = <0xf0>;
		clocks = <&ext_32k>, <&ext_26m>, <&ext_26m>,
			 <&ext_rc0_4m>, <&clk_dpll_41m7>, <&clk_twpll_48m>;
		clock-output-names = "clk_aux1";
	};

	clk_aux2: clk-aux2 {
		compatible = "sprd,composite-clock";
		#clock-cells = <0>;
		reg = <0 0x402e0088 0 0x4>,
			<0 0x402e008c 0 0x4>;
		sprd,mux-msk = <0x1f0000>;
		sprd,div-msk = <0xf00>;
		clocks = <&ext_32k>, <&ext_26m>, <&ext_26m>,
			 <&ext_rc0_4m>, <&clk_dpll_41m7>, <&clk_twpll_48m>;
		clock-output-names = "clk_aux2";
	};

	clk_probe: clk-probe {
		compatible = "sprd,composite-clock";
		#clock-cells = <0>;
		reg = <0 0x402e0088 0 0x4>,
			<0 0x402e008c 0 0x4>;
		sprd,mux-msk = <0x1f000000>;
		sprd,div-msk = <0xf000>;
		clocks = <&ext_32k>, <&ext_26m>, <&ext_26m>,
			 <&ext_rc0_4m>, <&clk_dpll_41m7>, <&clk_twpll_48m>;
		clock-output-names = "clk_probe";
	};

	/* GPU Sys Clock */
	clk_gpu: clk@60100004 {
		compatible = "sprd,composite-clock";
		#clock-cells = <0>;
		reg = <0 0x60100004 0 0x4>;
		sprd,mux-msk = <0x7>;
		sprd,div-msk = <0x30>;
		clocks = <&clk_twpll_153m6>, <&clk_twpll_192m>,
			 <&clk_twpll_256m>, <&clk_twpll_307m2>,
			 <&clk_twpll_384m>, <&clk_twpll_512m>,
			 <&clk_gpll>;
		clock-output-names = "clk_gpu";
	};

	/* Camera Sys Clock */
	clk_mm_ahb_gates: clk@60d00000 {
		compatible = "sprd,gates-clock";
		#clock-cells = <1>;
		reg = <0 0x60d00000 0 0x4>;
		sprd,gates-msk = <0x1ff>;
		clocks = <&clk_mm_ahb>;
		clock-output-names = "dcam_eb", "isp_eb", "vsp_eb",
				     "csi_eb", "csi_s_eb", "jpg_eb",
				     "ckg_eb", "cpp_eb", "cbm_eb";
	};

	clk_mm_ckg_gates: clk@60d00008 {
		compatible = "sprd,gates-clock";
		#clock-cells = <1>;
		reg = <0 0x60d00008 0 0x4>;
		sprd,gates-msk = <0x3f>;
		clocks = <&clk_mm_ahb>;
		clock-output-names = "cphy_cfg_ckg_en", "sensor0_ckg_en",
				     "sensor1_ckg_en", "isp_axi_ckg_en",
				     "mcsi_ckg_en", "mcsi_s_ckg_en";
	};

	clk_mm_ahb: clk@60e00020 {
		compatible = "sprd,muxed-clock";
		#clock-cells = <0>;
		reg = <0 0x60e00020 0 0x4>;
		sprd,mux-msk = <0x3>;
		clocks = <&ext_26m>, <&clk_twpll_96m>,
			 <&clk_twpll_128m>, <&clk_twpll_153m6>;
		clock-output-names = "clk_mm_ahb";
	};

	clk_sensor0: clk@60e00024 {
		compatible = "sprd,composite-clock";
		#clock-cells = <0>;
		reg = <0 0x60e00024 0 0x4>;
		sprd,mux-msk = <0x3>;
		sprd,div-msk = <0x700>;
		clocks = <&ext_26m>, <&clk_twpll_48m>,
			 <&clk_twpll_76m8>, <&clk_twpll_96m>;
		clock-output-names = "clk_sensor0";
	};

	clk_sensor1: clk@60e00028 {
		compatible = "sprd,composite-clock";
		#clock-cells = <0>;
		reg = <0 0x60e00028 0 0x4>;
		sprd,mux-msk = <0x3>;
		sprd,div-msk = <0x700>;
		clocks = <&ext_26m>, <&clk_twpll_48m>,
			 <&clk_twpll_76m8>, <&clk_twpll_96m>;
		clock-output-names = "clk_sensor1";
	};

	clk_dcam_if: clk@60e0002c {
		compatible = "sprd,muxed-clock";
		#clock-cells = <0>;
		reg = <0 0x60e0002c 0 0x4>;
		sprd,mux-msk = <0x3>;
		clocks = <&clk_twpll_128m>, <&clk_twpll_256m>,
			 <&clk_twpll_307m2>, <&clk_twpll_384m>;
		clock-output-names = "clk_dcam_if";
	};

	clk_vsp: clk@60e00030 {
		compatible = "sprd,muxed-clock";
		#clock-cells = <0>;
		reg = <0 0x60e00030 0 0x4>;
		sprd,mux-msk = <0x3>;
		clocks = <&clk_twpll_76m8>, <&clk_twpll_128m>,
			 <&clk_twpll_256m>, <&clk_twpll_307m2>;
		clock-output-names = "clk_vsp";
	};

	clk_isp: clk@60e00034 {
		compatible = "sprd,muxed-clock";
		#clock-cells = <0>;
		reg = <0 0x60e00034 0 0x4>;
		sprd,mux-msk = <0x7>;
		clocks = <&clk_twpll_128m>, <&clk_twpll_256m>,
			 <&clk_twpll_307m2>, <&clk_twpll_384m>,
			 <&clk_cppll>;
		clock-output-names = "clk_isp";
	};

	clk_jpg: clk@60e00038 {
		compatible = "sprd,muxed-clock";
		#clock-cells = <0>;
		reg = <0 0x60e00038 0 0x4>;
		sprd,mux-msk = <0x3>;
		clocks = <&clk_twpll_76m8>, <&clk_twpll_128m>,
			 <&clk_twpll_256m>, <&clk_twpll_307m2>;
		clock-output-names = "clk_jpg";
	};

	clk_mipi_csi: clk@60e0003c {
		compatible = "sprd,muxed-clock";
		#clock-cells = <0>;
		reg = <0 0x60e0003c 0 0x4>;
		sprd,mux-msk = <0x1>;
		clocks = <&clk_twpll_76m8>, <&clk_twpll_192m>;
		clock-output-names = "clk_mipi_csi";
	};

	clk_cpp: clk@60e00040 {
		compatible = "sprd,muxed-clock";
		#clock-cells = <0>;
		reg = <0 0x60e00040 0 0x4>;
		sprd,mux-msk = <0x3>;
		clocks = <&clk_twpll_76m8>, <&clk_twpll_128m>,
			 <&clk_twpll_256m>, <&clk_twpll_307m2>;
		clock-output-names = "clk_cpp";
	};

	clk_mipi_csi_s: clk@60e00044 {
		compatible = "sprd,muxed-clock";
		#clock-cells = <0>;
		reg = <0 0x60e00044 0 0x4>;
		sprd,mux-msk = <0x1>;
		clocks = <&clk_twpll_76m8>, <&clk_twpll_192m>;
		clock-output-names = "clk_mipi_csi_s";
	};

	/* Ap Ahb Gates */
	clk_ap_ahb_gates: clk@20e00000 {
		compatible = "sprd,sc1000-gates-clock";
		#clock-cells = <1>;
		reg = <0 0x20e00000 0 0x3000>;
		sprd,gates-msk = <0x78801ffb>;
		/* need to change to clk_ap_ahb later */
		clocks = <&ext_26m>;
		clock-output-names = "dsi_eb", "dispc_eb", "gsp_eb",
				     "otg_eb", "dma_eb", "ce_pub_eb",
				     "nandc_eb", "sdio0_eb", "sdio1_eb",
				     "sdio2_eb", "emmc_eb", "ce_sec_eb",
				     "ce_efuse_eb", "emmc_32k_eb",
				     "sdio0_32k_eb", "sdio1_32k_eb", "sdio2_32k_eb";
	};

	/* Aon Apb Gates */
	clk_aon_apb_gates0: clk@402e0000 {
		compatible = "sprd,sc1000-gates-clock";
		#clock-cells = <1>;
		reg = <0 0x402e0000 0 0x3000>;
		sprd,gates-msk = <0xffffffff>;
		clocks = <&clk_aon_apb>;
		clock-output-names = "adc_eb", "fm_eb", "tpc_eb",
				     "gpio_eb", "pwm0_eb", "pwm1_eb",
				     "pwm2_eb", "pwm3_eb", "kpd_eb",
				     "aon_syst_eb", "ap_syst_eb", "aon_tmr_eb",
				     "ap_tmr0_eb", "efuse_eb", "eic_eb",
				     "intc_eb", "adi_eb", "audif_eb",
				     "aud_eb", "vbc_eb", "pin_eb",
				     "ipi_eb", "splk_eb", "mspi_eb",
				     "ap_wdg_eb", "mm_eb", "aon_apb_ckg_eb",
				     "gpu_eb", "ca7_ts0_eb", "ca7_ts1_eb",
				     "ca7_dap_eb", "i2c_eb";
	};

	clk_aon_apb_gates1: clk@402e0004 {
		compatible = "sprd,sc1000-gates-clock";
		#clock-cells = <1>;
		reg = <0 0x402e0004 0 0x3000>;
		sprd,gates-msk = <0xffffffff>;
		clocks = <&clk_aon_apb>;
		clock-output-names = "pmu_eb", "thm_eb", "aux0_eb",
				     "aux1_eb", "aux2_eb", "probe_eb",
				     "avs_eb", "clk_emc_ref_eb", "ca7_wdg_eb",
				     "ap_tmr1_eb", "ap_tmr2_eb", "disp_emc_eb",
				     "zip_emc_eb", "gsp_emc_eb", "mm_vsp_eb",
				     "lvds_trx_eb", "lvds_tcxo_eb", "mdar_eb",
				     "rtc4m0_cal_eb", "rtc4m1_cal_eb", "djtag_eb",
				     "mbox_eb", "aon_dma_eb", "arm7_djtag_eb",
				     "lvds_pll_div_en", "def_eb", "ca5_ts0_eb",
				     "orp_jtag_eb", "dbg_eb", "dbg_emc_eb",
				     "cross_trig_eb", "serdes_dphy_eb";
	};

	clk_aon_apb_rtc_gates: clk@402e0010 {
		compatible = "sprd,sc1000-gates-clock";
		#clock-cells = <1>;
		reg = <0 0x402e0010 0 0x3000>;
		sprd,gates-msk = <0x7ffff>;
		clocks = <&clk_aon_apb>;
		clock-output-names = "arch_rtc_eb", "kpb_rtc_eb", "aon_syst_rtc_eb",
				     "ap_syst_rtc_eb", "aon_tmr_rtc_eb", "ap_tmr0_rtc_eb",
				     "eic_rtc_eb", "eic_rtcdv5_eb", "ap_wdg_rtc_eb",
				     "ca7_wdg_rtc_eb", "thm_rtc_eb", "athma_rtc_eb",
				     "gthma_rtc_eb", "athma_rtc_a_en",
				     "gthma_rtc_a_en", "ap_trm1_rtc_eb",
				     "ap_tmr2_rtc_eb", "dxco_lc_rtc_eb",
				     "bb_cal_rtc_eb";
	};

	clk_aon_apb_gates2: clk@402e00b0 {
		compatible = "sprd,sc1000-gates-clock";
		#clock-cells = <1>;
		reg = <0x0 0x402e00b0 0x0 0x3000>;
		sprd,gates-msk = <0x1fffff71>;
		clocks = <&clk_aon_apb>;
		clock-output-names = "wcdma_eb", "cssys_eb", "dmc_eb",
				     "pub_reg_eb", "s_d_cfg_eb", "s_d_ref_eb",
				     "b_dma_eb", "anlg_eb", "pin_apb_eb",
				     "anlg_apb_eb", "bsmtmr_eb", "ap_axi_eb",
				     "ap_intc0_eb", "ap_intc1_eb", "ap_intc2_eb",
				     "ap_intc3_eb", "ap_intc4_eb", "ap_intc5_eb",
				     "scc_eb", "dphy_cfg_eb", "dphy_ref_eb",
				     "cphy_cfg_eb", "otg_ref_eb", "serdes_eb",
				     "emc_eb";
	};

	clk_aon_eb0_gates: clk@402e0134 {
		compatible = "sprd,sc1000-gates-clock";
		#clock-cells = <1>;
		reg = <0 0x402e0134 0 0x3000>;
		sprd,gates-msk = <0x380fff>;
		clocks = <&clk_aon_apb>;
		clock-output-names = "emmc_1x_eb", "emmc_2x_eb", "sdio0_1x_eb",
				     "sdio0_2x_eb", "sdio1_1x_eb", "sdio1_2x_eb",
				     "sdio2_1x_eb", "sdio2_2x_eb", "cssys_ca7_eb",
				     "ap_hs_spi_eb", "det_32k_eb", "tmr_eb",
				     "nandc_async_eb", "nandc_1x_eb", "nandc_2x_eb";
	};

	/* Ap Apb getes */
	clk_ap_apb_gates: clk@71300000 {
		compatible = "sprd,sc1000-gates-clock";
		#clock-cells = <1>;
		reg = <0 0x71300000 0 0x3000>;
		sprd,gates-msk = <0x7ffff>;
		clocks = <&clk_ap_apb>;
		clock-output-names = "sim0_eb", "iis0_eb", "iis1_eb",
				     "iis2_eb", "iis3_eb", "spi0_eb",
				     "spi1_eb", "spi2_eb", "i2c0_eb",
				     "i2c1_eb", "i2c2_eb", "i2c3_eb",
				     "i2c4_eb", "uart0_eb", "uart1_eb",
				     "uart2_eb", "uart3_eb", "uart4_eb",
				     "sim0_32k_eb";
	};
};

